AUTOSAR XML (schema 4-2-1)
package /RootP_IntDcm
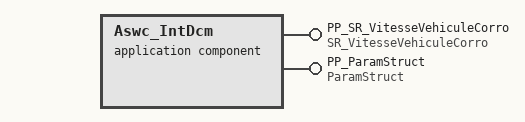
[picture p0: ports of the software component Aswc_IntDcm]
  application sw component type Aswc_IntDcm
    provide/require port PRP_SR_VitesseVehicule: provided-required-interface=SR_VitesseVehicule
    provide port PP_SR_VitesseVehiculeCorro: provided-interface=SR_VitesseVehiculeCorro
    provide port PP_ParamStruct: provided-interface=ParamStruct
  application sw component type AswcDiagForDcm
    provide/require port PRP_SR_VitesseVehiculeCorro: provided-required-interface=SR_VitesseVehiculeCorro
package /RootP_Composition
  composition sw component type Compo_VSM
    component Instance_ASWC_M741: type=ASWC_M741
